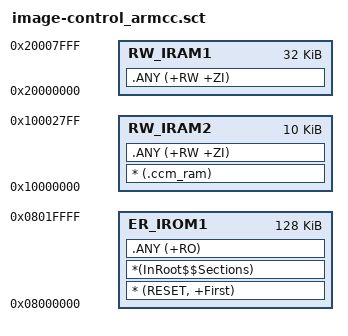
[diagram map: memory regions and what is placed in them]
LR_IROM1 0x08000000 0x00020000  {
  ER_IROM1 0x08000000 0x00020000  {
    * (RESET, +First)
    *(InRoot$$Sections)
    .ANY (+RO)
  }

  RW_IRAM1 0x20000000 0x00008000  {
    .ANY (+RW +ZI)
  }

  RW_IRAM2 0x10000000 0x00002800  {
    * (.ccm_ram)
    .ANY (+RW +ZI)
  }
}
